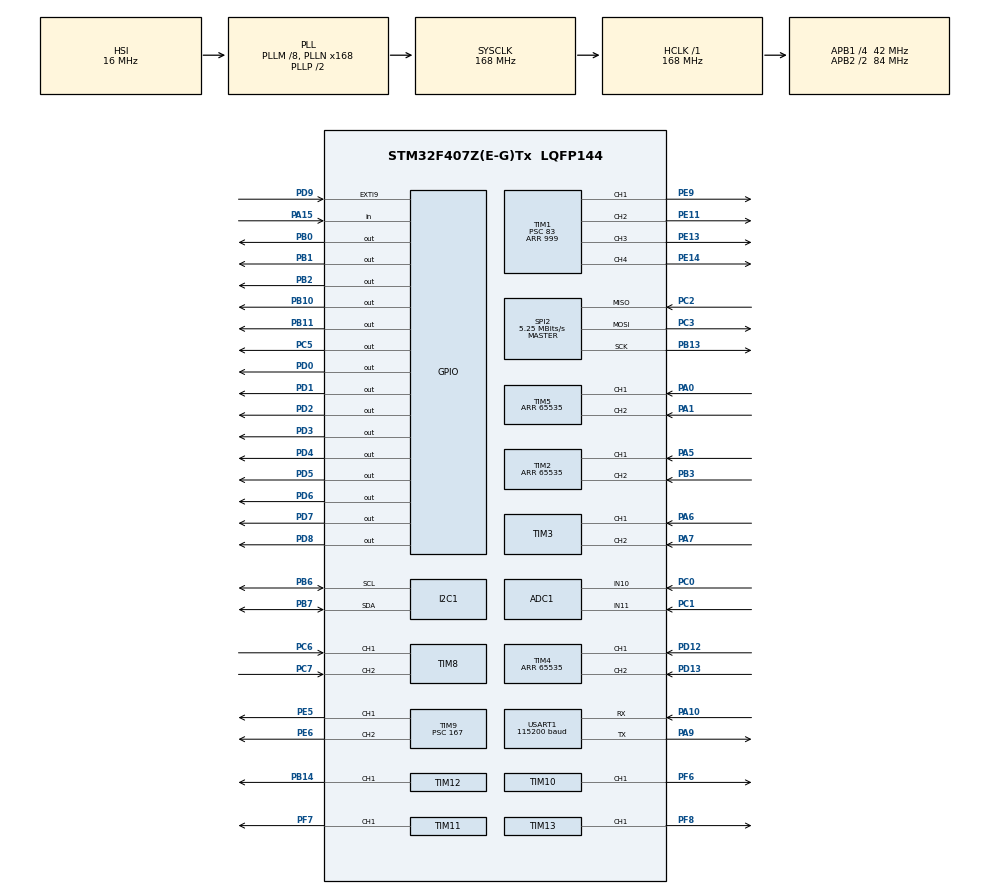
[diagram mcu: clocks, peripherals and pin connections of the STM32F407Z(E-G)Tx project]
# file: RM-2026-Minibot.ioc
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ADC1.Channel-0\#ChannelRegularConversion=ADC_CHANNEL_10
ADC1.Channel-1\#ChannelRegularConversion=ADC_CHANNEL_11
ADC1.DMAContinuousRequests=ENABLE
ADC1.NbrOfConversion=2
ADC1.NbrOfConversionFlag=1
ADC1.Rank-0\#ChannelRegularConversion=1
ADC1.Rank-1\#ChannelRegularConversion=2
ADC1.SamplingTime-0\#ChannelRegularConversion=ADC_SAMPLETIME_28CYCLES
ADC1.SamplingTime-1\#ChannelRegularConversion=ADC_SAMPLETIME_28CYCLES
ADC1.ScanConvMode=ENABLE
ADC1.master=1
Dma.ADC1.0.Direction=DMA_PERIPH_TO_MEMORY
Dma.ADC1.0.FIFOMode=DMA_FIFOMODE_DISABLE
Dma.ADC1.0.Instance=DMA2_Stream0
Dma.ADC1.0.MemDataAlignment=DMA_MDATAALIGN_HALFWORD
Dma.ADC1.0.MemInc=DMA_MINC_ENABLE
Dma.ADC1.0.Mode=DMA_CIRCULAR
Dma.ADC1.0.PeriphDataAlignment=DMA_PDATAALIGN_HALFWORD
Dma.ADC1.0.PeriphInc=DMA_PINC_DISABLE
Dma.ADC1.0.Priority=DMA_PRIORITY_LOW
Dma.Request0=ADC1
FREERTOS.INCLUDE_vTaskDelayUntil=1
FREERTOS.Tasks01=defaultTask,0,768,StartDefaultTask,As weak,NULL,Dynamic,NULL,NULL;MotorTast,1,384,StartMotorTast,As weak,NULL,Dynamic,NULL,NULL;CommTask,2,256,StartCommTask,As weak,NULL,Dynamic,NULL,NULL;ArmOledTask,0,384,StartArmOledTask,As weak,NULL,Dynamic,NULL,NULL
Mcu.Family=STM32F4
Mcu.Name=STM32F407Z(E-G)Tx
Mcu.Package=LQFP144
NVIC.DMA2_Stream0_IRQn=true\:5\:0\:false\:false\:true\:true\:false\:true\:true
NVIC.EXTI9_5_IRQn=true\:5\:0\:true\:false\:true\:true\:true\:true\:true
NVIC.PriorityGroup=NVIC_PRIORITYGROUP_4
NVIC.TIM6_DAC_IRQn=true\:15\:0\:false\:false\:true\:false\:false\:true\:true
NVIC.TimeBase=TIM6_DAC_IRQn
NVIC.TimeBaseIP=TIM6
PA0-WKUP.Signal=S_TIM5_CH1
PA1.Signal=S_TIM5_CH2
PA13.Mode=Serial_Wire
PA13.Signal=SYS_JTMS-SWDIO
PA14.Mode=Serial_Wire
PA14.Signal=SYS_JTCK-SWCLK
PA15.GPIO_PuPd=GPIO_PULLUP
PA15.Signal=GPIO_Input
PA5.Signal=S_TIM2_CH1_ETR
PA6.Signal=S_TIM3_CH1
PA7.Signal=S_TIM3_CH2
PB0.Signal=GPIO_Output
PB1.Signal=GPIO_Output
PB10.Signal=GPIO_Output
PB11.Signal=GPIO_Output
PB13.Mode=Full_Duplex_Master
PB13.Signal=SPI2_SCK
PB14.Signal=S_TIM12_CH1
PB2.Signal=GPIO_Output
PB3.Signal=S_TIM2_CH2
PB6.Mode=I2C
PB6.Signal=I2C1_SCL
PB7.Mode=I2C
PB7.Signal=I2C1_SDA
PC0.Signal=ADCx_IN10
PC1.Signal=ADCx_IN11
PC14-OSC32_IN.Mode=LSE-External-Oscillator
PC14-OSC32_IN.Signal=RCC_OSC32_IN
PC15-OSC32_OUT.Mode=LSE-External-Oscillator
PC15-OSC32_OUT.Signal=RCC_OSC32_OUT
PC2.Mode=Full_Duplex_Master
PC2.Signal=SPI2_MISO
PC3.Mode=Full_Duplex_Master
PC3.Signal=SPI2_MOSI
PC5.Signal=GPIO_Output
PC6.Signal=S_TIM8_CH1
PC7.Signal=S_TIM8_CH2
PD0.Signal=GPIO_Output
PD1.Signal=GPIO_Output
PD12.Signal=S_TIM4_CH1
PD13.Signal=S_TIM4_CH2
PD2.Signal=GPIO_Output
PD3.Signal=GPIO_Output
PD4.Signal=GPIO_Output
PD5.Signal=GPIO_Output
PD6.Signal=GPIO_Output
PD7.Signal=GPIO_Output
PD8.Signal=GPIO_Output
PD9.Signal=GPXTI9
PE11.Signal=S_TIM1_CH2
PE13.Signal=S_TIM1_CH3
PE14.Signal=S_TIM1_CH4
PE5.Signal=S_TIM9_CH1
PE6.Signal=S_TIM9_CH2
PE9.Signal=S_TIM1_CH1
PF6.Signal=S_TIM10_CH1
PF7.Signal=S_TIM11_CH1
PF8.Signal=S_TIM13_CH1
PH0-OSC_IN.Mode=HSE-External-Oscillator
PH0-OSC_IN.Signal=RCC_OSC_IN
PH1-OSC_OUT.Mode=HSE-External-Oscillator
PH1-OSC_OUT.Signal=RCC_OSC_OUT
ProjectManager.HeapSize=0x200
ProjectManager.StackSize=0x400
ProjectManager.TargetToolchain=CMake
RCC.48MHZClocksFreq_Value=84000000
RCC.AHBFreq_Value=168000000
RCC.APB1CLKDivider=RCC_HCLK_DIV4
RCC.APB1Freq_Value=42000000
RCC.APB1TimFreq_Value=84000000
RCC.APB2CLKDivider=RCC_HCLK_DIV2
RCC.APB2Freq_Value=84000000
RCC.APB2TimFreq_Value=168000000
RCC.CortexFreq_Value=168000000
RCC.HCLKFreq_Value=168000000
RCC.HSE_VALUE=25000000
RCC.HSI_VALUE=16000000
RCC.PLLM=8
RCC.PLLN=168
RCC.SYSCLKFreq_VALUE=168000000
RCC.SYSCLKSource=RCC_SYSCLKSOURCE_PLLCLK
RCC.VCOOutputFreq_Value=336000000
SH.ADCx_IN10.0=ADC1_IN10,IN10
SH.ADCx_IN11.0=ADC1_IN11,IN11
SH.S_TIM10_CH1.0=TIM10_CH1,PWM Generation1 CH1
SH.S_TIM11_CH1.0=TIM11_CH1,PWM Generation1 CH1
SH.S_TIM12_CH1.0=TIM12_CH1,PWM Generation1 CH1
SH.S_TIM13_CH1.0=TIM13_CH1,PWM Generation1 CH1
SH.S_TIM1_CH1.0=TIM1_CH1,PWM Generation1 CH1
SH.S_TIM1_CH2.0=TIM1_CH2,PWM Generation2 CH2
SH.S_TIM1_CH3.0=TIM1_CH3,PWM Generation3 CH3
SH.S_TIM1_CH4.0=TIM1_CH4,PWM Generation4 CH4
SH.S_TIM2_CH1_ETR.0=TIM2_CH1,Encoder_Interface
SH.S_TIM2_CH2.0=TIM2_CH2,Encoder_Interface
SH.S_TIM3_CH1.0=TIM3_CH1,Encoder_Interface
SH.S_TIM3_CH2.0=TIM3_CH2,Encoder_Interface
SH.S_TIM4_CH1.0=TIM4_CH1,Encoder_Interface
SH.S_TIM4_CH2.0=TIM4_CH2,Encoder_Interface
SH.S_TIM5_CH1.0=TIM5_CH1,Encoder_Interface
SH.S_TIM5_CH2.0=TIM5_CH2,Encoder_Interface
SH.S_TIM8_CH1.0=TIM8_CH1,Encoder_Interface
SH.S_TIM8_CH2.0=TIM8_CH2,Encoder_Interface
SH.S_TIM9_CH1.0=TIM9_CH1,PWM Generation1 CH1
SH.S_TIM9_CH2.0=TIM9_CH2,PWM Generation2 CH2
SPI2.BaudRatePrescaler=SPI_BAUDRATEPRESCALER_8
SPI2.CalculateBaudRate=5.25 MBits/s
SPI2.Direction=SPI_DIRECTION_2LINES
SPI2.Mode=SPI_MODE_MASTER
SPI2.VirtualType=VM_MASTER
TIM1.Channel-PWM\ Generation1\ CH1=TIM_CHANNEL_1
TIM1.Channel-PWM\ Generation2\ CH2=TIM_CHANNEL_2
TIM1.Channel-PWM\ Generation3\ CH3=TIM_CHANNEL_3
TIM1.Channel-PWM\ Generation4\ CH4=TIM_CHANNEL_4
TIM1.Period=999
TIM1.Prescaler=83
TIM10.Channel=TIM_CHANNEL_1
TIM10.Period=19999
TIM10.Prescaler=167
TIM11.Channel=TIM_CHANNEL_1
TIM11.Period=19999
TIM11.Prescaler=167
TIM12.Channel-PWM\ Generation1\ CH1=TIM_CHANNEL_1
TIM12.Period=19999
TIM12.Prescaler=83
TIM13.Channel=TIM_CHANNEL_1
TIM13.Period=999
TIM13.Prescaler=41
TIM2.EncoderMode=TIM_ENCODERMODE_TI12
TIM2.IC1Filter=4
TIM2.IC2Filter=4
TIM2.Period=65535
TIM3.EncoderMode=TIM_ENCODERMODE_TI12
TIM3.IC1Filter=4
TIM3.IC2Filter=4
TIM4.EncoderMode=TIM_ENCODERMODE_TI12
TIM4.IC1Filter=4
TIM4.IC2Filter=4
TIM4.Period=65535
TIM5.EncoderMode=TIM_ENCODERMODE_TI12
TIM5.IC1Filter=4
TIM5.IC2Filter=4
TIM5.Period=65535
TIM8.EncoderMode=TIM_ENCODERMODE_TI12
TIM8.IC1Filter=4
TIM8.IC2Filter=4
TIM9.Channel-PWM\ Generation1\ CH1=TIM_CHANNEL_1
TIM9.Channel-PWM\ Generation2\ CH2=TIM_CHANNEL_2
TIM9.Period=19999
TIM9.Prescaler=167
VP_FREERTOS_VS_CMSIS_V1.Mode=CMSIS_V1
VP_SYS_VS_tim6.Mode=TIM6
VP_TIM10_VS_ClockSourceINT.Mode=Enable_Timer
VP_TIM11_VS_ClockSourceINT.Mode=Enable_Timer
VP_TIM12_VS_ClockSourceINT.Mode=Enable_Timer
VP_TIM13_VS_ClockSourceINT.Mode=Enable_Timer
VP_TIM1_VS_ClockSourceINT.Mode=Internal
VP_TIM9_VS_ClockSourceINT.Mode=Internal
board=custom
PA9.Mode=Asynchronous
PA9.Signal=USART1_TX
PA10.Mode=Asynchronous
PA10.GPIO_PuPd=GPIO_PULLUP
PA10.Signal=USART1_RX
USART1.BaudRate=115200
USART1.VirtualMode=VM_ASYNC
NVIC.USART1_IRQn=true\:5\:0\:false\:false\:true\:true\:true\:true\:true

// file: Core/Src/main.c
/* USER CODE BEGIN Header */
/**
  ******************************************************************************
  * @file           : main.c
  * @brief          : Main program body
  ******************************************************************************
  * @attention
  *
  * Copyright (c) 2026 STMicroelectronics.
  * All rights reserved.
  *
  * This software is licensed under terms that can be found in the LICENSE file
  * in the root directory of this software component.
  * If no LICENSE file comes with this software, it is provided AS-IS.
  *
  ******************************************************************************
  */
/* USER CODE END Header */
#include "main.h"
#include "cmsis_os.h"
#include "adc.h"
#include "dma.h"
#include "i2c.h"
#include "spi.h"
#include "tim.h"
#include "usart.h"
#include "gpio.h"

/* USER CODE BEGIN Includes */
#include "robot/robot.h"
#include "fault_handler.h"

/* USER CODE END Includes */

void SystemClock_Config(void);
void MX_FREERTOS_Init(void);

int main(void)
{

  /* MCU Configuration--------------------------------------------------------*/

  /* Reset of all peripherals, Initializes the Flash interface and the Systick. */
  HAL_Init();

  /* Configure the system clock */
  SystemClock_Config();

  /* Initialize all configured peripherals */
  MX_GPIO_Init();
  MX_DMA_Init();
  MX_TIM1_Init();
  MX_ADC1_Init();
  MX_I2C1_Init();
  MX_SPI2_Init();
  MX_TIM2_Init();
  MX_TIM3_Init();
  MX_TIM4_Init();
  MX_TIM5_Init();
  MX_TIM8_Init();
  MX_TIM9_Init();
  MX_TIM10_Init();
  MX_TIM11_Init();
  MX_TIM12_Init();
  MX_TIM13_Init();
  MX_USART1_UART_Init();
  /* USER CODE BEGIN 2 */

  if(!Robot_Init())Error_Handler();

  /* USER CODE END 2 */

  /* Call init function for freertos objects (in cmsis_os2.c) */
  MX_FREERTOS_Init();

  /* Start scheduler */
  osKernelStart();

  /* We should never get here as control is now taken by the scheduler */

  /* Infinite loop */
  while (1)
  {

  }
}

void SystemClock_Config(void)
{
  RCC_OscInitTypeDef RCC_OscInitStruct = {0};
  RCC_ClkInitTypeDef RCC_ClkInitStruct = {0};

  /** Configure the main internal regulator output voltage
  */
  __HAL_RCC_PWR_CLK_ENABLE();
  __HAL_PWR_VOLTAGESCALING_CONFIG(PWR_REGULATOR_VOLTAGE_SCALE1);

  /** Initializes the RCC Oscillators according to the specified parameters
  * in the RCC_OscInitTypeDef structure.
  */
  RCC_OscInitStruct.OscillatorType = RCC_OSCILLATORTYPE_HSI;
  RCC_OscInitStruct.HSIState = RCC_HSI_ON;
  RCC_OscInitStruct.HSICalibrationValue = RCC_HSICALIBRATION_DEFAULT;
  RCC_OscInitStruct.PLL.PLLState = RCC_PLL_ON;
  RCC_OscInitStruct.PLL.PLLSource = RCC_PLLSOURCE_HSI;
  RCC_OscInitStruct.PLL.PLLM = 8;
  RCC_OscInitStruct.PLL.PLLN = 168;
  RCC_OscInitStruct.PLL.PLLP = RCC_PLLP_DIV2;
  RCC_OscInitStruct.PLL.PLLQ = 4;
  if (HAL_RCC_OscConfig(&RCC_OscInitStruct) != HAL_OK)
  {
    Error_Handler();
  }

  /** Initializes the CPU, AHB and APB buses clocks
  */
  RCC_ClkInitStruct.ClockType = RCC_CLOCKTYPE_HCLK|RCC_CLOCKTYPE_SYSCLK
                              |RCC_CLOCKTYPE_PCLK1|RCC_CLOCKTYPE_PCLK2;
  RCC_ClkInitStruct.SYSCLKSource = RCC_SYSCLKSOURCE_PLLCLK;
  RCC_ClkInitStruct.AHBCLKDivider = RCC_SYSCLK_DIV1;
  RCC_ClkInitStruct.APB1CLKDivider = RCC_HCLK_DIV4;
  RCC_ClkInitStruct.APB2CLKDivider = RCC_HCLK_DIV2;

  if (HAL_RCC_ClockConfig(&RCC_ClkInitStruct, FLASH_LATENCY_5) != HAL_OK)
  {
    Error_Handler();
  }
}

void HAL_TIM_PeriodElapsedCallback(TIM_HandleTypeDef *htim)
{
  if (htim->Instance == TIM6)
  {
    HAL_IncTick();
  }
}

void Error_Handler(void)
{
  /* USER CODE BEGIN Error_Handler_Debug */
  /* User can add his own implementation to report the HAL error return state */
  BSP_EmergencyHalt(6U);
  /* USER CODE END Error_Handler_Debug */
}

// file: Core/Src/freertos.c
/* USER CODE BEGIN Header */
/**
  ******************************************************************************
  * File Name          : freertos.c
  * Description        : Code for freertos applications
  ******************************************************************************
  * @attention
  *
  * Copyright (c) 2026 STMicroelectronics.
  * All rights reserved.
  *
  * This software is licensed under terms that can be found in the LICENSE file
  * in the root directory of this software component.
  * If no LICENSE file comes with this software, it is provided AS-IS.
  *
  ******************************************************************************
  */
/* USER CODE END Header */

#include "FreeRTOS.h"
#include "task.h"
#include "main.h"
#include "cmsis_os.h"

/* USER CODE BEGIN Includes */
#include "os_task.h"

/* USER CODE END Includes */

osThreadId defaultTaskHandle;
osThreadId MotorTastHandle;
osThreadId CommTaskHandle;
osThreadId ArmOledTaskHandle;

void StartDefaultTask(void const * argument);
void StartMotorTast(void const * argument);
void StartCommTask(void const * argument);
void StartArmOledTask(void const * argument);

void MX_FREERTOS_Init(void); /* (MISRA C 2004 rule 8.1) */

/* GetIdleTaskMemory prototype (linked to static allocation support) */
void vApplicationGetIdleTaskMemory( StaticTask_t **ppxIdleTaskTCBBuffer, StackType_t **ppxIdleTaskStackBuffer, uint32_t *pulIdleTaskStackSize );

/* USER CODE BEGIN GET_IDLE_TASK_MEMORY */
static StaticTask_t xIdleTaskTCBBuffer;
static StackType_t xIdleStack[configMINIMAL_STACK_SIZE];

void vApplicationGetIdleTaskMemory( StaticTask_t **ppxIdleTaskTCBBuffer, StackType_t **ppxIdleTaskStackBuffer, uint32_t *pulIdleTaskStackSize )
{
  *ppxIdleTaskTCBBuffer = &xIdleTaskTCBBuffer;
  *ppxIdleTaskStackBuffer = &xIdleStack[0];
  *pulIdleTaskStackSize = configMINIMAL_STACK_SIZE;
  /* place for user code */
}
/* USER CODE END GET_IDLE_TASK_MEMORY */

void MX_FREERTOS_Init(void) {

  /* Create the thread(s) */
  /* definition and creation of defaultTask */
  osThreadDef(defaultTask, StartDefaultTask, osPriorityNormal, 0, 768);
  defaultTaskHandle = osThreadCreate(osThread(defaultTask), NULL);

  /* definition and creation of MotorTast */
  osThreadDef(MotorTast, StartMotorTast, osPriorityAboveNormal, 0, 384);
  MotorTastHandle = osThreadCreate(osThread(MotorTast), NULL);

  /* definition and creation of CommTask */
  osThreadDef(CommTask, StartCommTask, osPriorityHigh, 0, 256);
  CommTaskHandle = osThreadCreate(osThread(CommTask), NULL);

  /* definition and creation of ArmOledTask */
  osThreadDef(ArmOledTask, StartArmOledTask, osPriorityNormal, 0, 384);
  ArmOledTaskHandle = osThreadCreate(osThread(ArmOledTask), NULL);

}

__weak void StartDefaultTask(void const * argument)
{
  for(;;)
  {
    osDelay(1);
  }
}

__weak void StartMotorTast(void const * argument)
{
  for(;;)
  {
    osDelay(1);
  }
}

__weak void StartCommTask(void const * argument)
{
  for(;;)
  {
    osDelay(1);
  }
}

__weak void StartArmOledTask(void const * argument)
{
  /* USER CODE BEGIN StartArmOledTask */
  /* Infinite loop */
  for(;;)
  {
    osDelay(10);
  }
  /* USER CODE END StartArmOledTask */
}
